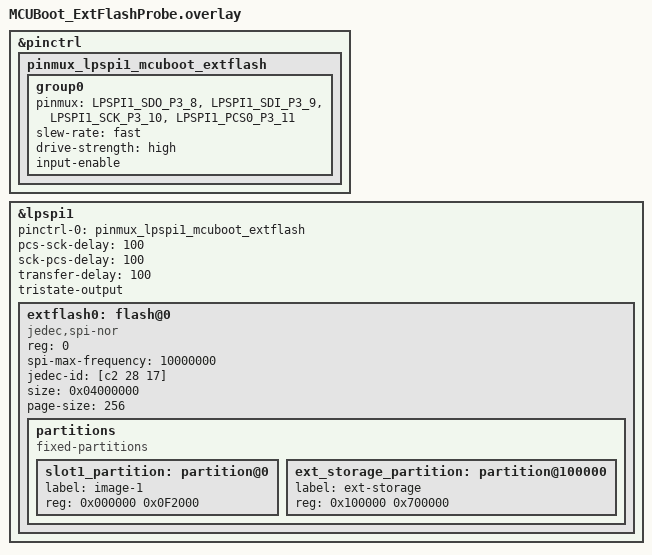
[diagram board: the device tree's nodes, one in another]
#include <nxp/mcx/MCXA156VLL-pinctrl.h>

/*
 * MCUboot-only, non-destructive external-flash bring-up.
 *
 * The application continues to use its custom NXP SPI/quad-read driver. The
 * bootloader only needs standard 1-1-1 SPI NOR commands for image management,
 * so its own build uses Zephyr's SPI NOR driver.
 */
&pinctrl {
    pinmux_lpspi1_mcuboot_extflash: pinmux_lpspi1_mcuboot_extflash {
        group0 {
            pinmux = <LPSPI1_SDO_P3_8>,
                     <LPSPI1_SDI_P3_9>,
                     <LPSPI1_SCK_P3_10>,
                     <LPSPI1_PCS0_P3_11>;

            slew-rate = "fast";
            drive-strength = "high";
            input-enable;
        };
    };
};

&lpspi1 {
    status = "okay";

    pinctrl-0 = <&pinmux_lpspi1_mcuboot_extflash>;
    pinctrl-names = "default";

    pcs-sck-delay = <100>;
    sck-pcs-delay = <100>;
    transfer-delay = <100>;
    tristate-output;

    extflash0: flash@0 {
        compatible = "jedec,spi-nor";
        status = "okay";
        reg = <0>;
        spi-max-frequency = <10000000>;

        jedec-id = [c2 28 17];
        size = <0x04000000>;
        page-size = <256>;

        partitions {
            compatible = "fixed-partitions";
            #address-cells = <1>;
            #size-cells = <1>;

            /*
             * Swap-using-offset reserves the first 8 KiB sector and stores
             * the update image at offset 0x2000.  The secondary slot is one
             * 8 KiB sector larger than the 960 KiB primary slot.
             */
            slot1_partition: partition@0 {
                label = "image-1";
                reg = <0x000000 0x0F2000>;
            };

            /* 0x0F2000-0x0FFFFF is intentionally left unused. */
            ext_storage_partition: partition@100000 {
                label = "ext-storage";
                reg = <0x100000 0x700000>;
            };
        };
    };
};
